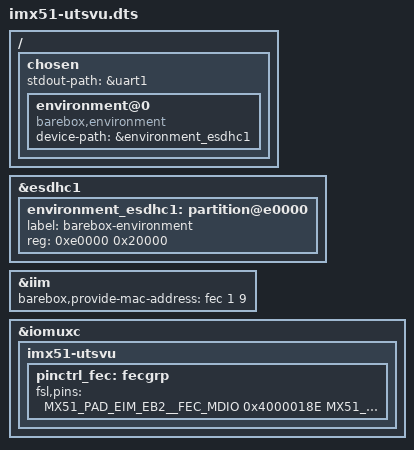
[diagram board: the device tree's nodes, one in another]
/*
 * Copyright 2011 Freescale Semiconductor, Inc.
 * Copyright 2011 Linaro Ltd.
 *
 * The code contained herein is licensed under the GNU General Public
 * License. You may obtain a copy of the GNU General Public License
 * Version 2 or later at the following locations:
 *
 * http://www.opensource.org/licenses/gpl-license.html
 * http://www.gnu.org/copyleft/gpl.html
 */

#include <arm/imx51-utsvu.dts>

/ {
	chosen {
		stdout-path = &uart1;

		environment@0 {
			compatible = "barebox,environment";
			device-path = &environment_esdhc1;
		};
	};
};

&esdhc1 {
	#address-cells = <1>;
	#size-cells = <1>;

	environment_esdhc1: partition@e0000 {
		label = "barebox-environment";
		reg = <0xe0000 0x20000>;
	};
};

&iim {
	barebox,provide-mac-address = <&fec 1 9>;
};

&iomuxc {
	imx51-utsvu {
		pinctrl_fec: fecgrp {
			/*
			 * Overwrite upstream FEC iomux settings since these currently
			 * have NO_PAD_CTRL instead of real settings. Remove this once
			 * this is fixed upstream.
			 */
			fsl,pins = <
				/* Management */
				MX51_PAD_EIM_EB2__FEC_MDIO		0x4000018E
				MX51_PAD_NANDF_CS3__FEC_MDC		0x4000018E
				/* Receive */
				MX51_PAD_EIM_CS4__FEC_RX_ER		0x80000000	/* Error while receive */
				MX51_PAD_NANDF_D11__FEC_RX_DV		0x00002187	/* RX Data valid */
				MX51_PAD_NANDF_RB3__FEC_RX_CLK		0x00002187	/* RX clock */
				MX51_PAD_NANDF_D9__FEC_RDATA0		0x80000000
				MX51_PAD_EIM_EB3__FEC_RDATA1		0x00000187
				MX51_PAD_EIM_CS2__FEC_RDATA2		0x00000187
				MX51_PAD_EIM_CS3__FEC_RDATA3		0x00000187
				/* Transmit */
				MX51_PAD_NANDF_CS7__FEC_TX_EN		0x80000000	/* Data present */
				MX51_PAD_NANDF_RDY_INT__FEC_TX_CLK	0x80000000	/* TX clock */
				MX51_PAD_NANDF_D8__FEC_TDATA0		0x80000000
				MX51_PAD_NANDF_CS4__FEC_TDATA1		0x80000000
				MX51_PAD_NANDF_CS5__FEC_TDATA2		0x80000000
				MX51_PAD_NANDF_CS6__FEC_TDATA3		0x80000000
				/* Control */
				MX51_PAD_NANDF_CS2__FEC_TX_ER		0x80000000	/* 100M transfer error */
				MX51_PAD_EIM_CS5__FEC_CRS		0x80000000	/* Carrier sense */
				MX51_PAD_NANDF_RB2__FEC_COL		0x00002187	/* Collision detect */
				/* Phy Reset */
				MX51_PAD_EIM_A20__GPIO2_14		0x00000087	 /* Phy Reset */
			>;
		};
	};
};
